VERSION ""

NS_ :

BS_:

BU_: CGEA12_TCU GWM PCM_HEV SOBDMC_HPCM_FD1 Vector__XXX

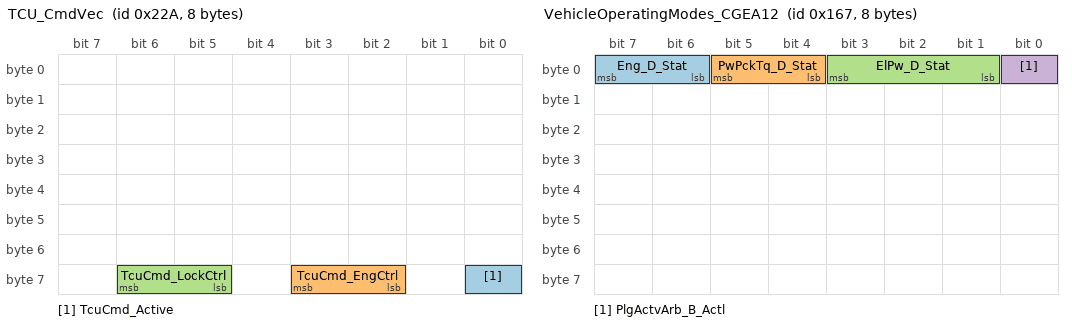
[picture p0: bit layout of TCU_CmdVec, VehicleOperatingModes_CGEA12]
BO_ 554 TCU_CmdVec: 8 CGEA12_TCU
 SG_ TcuCmd_Active   : 56|1@1+ (1,0) [0|1] "" Vector__XXX
 SG_ TcuCmd_EngCtrl  : 58|2@1+ (1,0) [0|3] "" Vector__XXX
 SG_ TcuCmd_LockCtrl : 61|2@1+ (1,0) [0|3] "" Vector__XXX

BO_ 359 VehicleOperatingModes_CGEA12: 8 PCM_HEV
 SG_ Eng_D_Stat        : 7|2@0+ (1,0) [0|3] "" CGEA12_TCU
 SG_ PwPckTq_D_Stat    : 5|2@0+ (1,0) [0|3] "" CGEA12_TCU
 SG_ ElPw_D_Stat       : 3|3@0+ (1,0) [0|7] "" CGEA12_TCU
 SG_ PlgActvArb_B_Actl : 0|1@0+ (1,0) [0|1] "" CGEA12_TCU

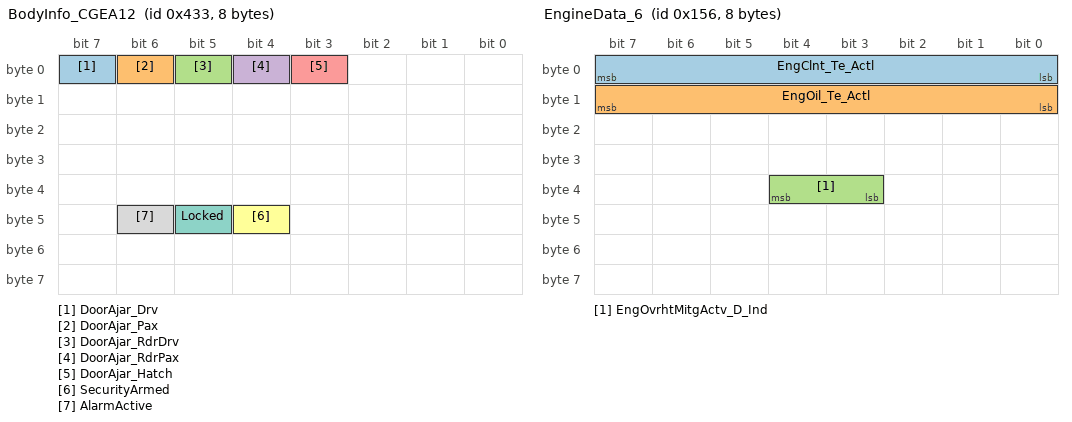
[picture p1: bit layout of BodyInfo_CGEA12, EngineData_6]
BO_ 1075 BodyInfo_CGEA12: 8 Vector__XXX
 SG_ DoorAjar_Drv    : 7|1@1+ (1,0) [0|1] "" CGEA12_TCU
 SG_ DoorAjar_Pax    : 6|1@1+ (1,0) [0|1] "" CGEA12_TCU
 SG_ DoorAjar_RdrDrv : 5|1@1+ (1,0) [0|1] "" CGEA12_TCU
 SG_ DoorAjar_RdrPax : 4|1@1+ (1,0) [0|1] "" CGEA12_TCU
 SG_ DoorAjar_Hatch  : 3|1@1+ (1,0) [0|1] "" CGEA12_TCU
 SG_ SecurityArmed   : 44|1@1+ (1,0) [0|1] "" CGEA12_TCU
 SG_ Locked          : 45|1@1+ (1,0) [0|1] "" CGEA12_TCU
 SG_ AlarmActive     : 46|1@1+ (1,0) [0|1] "" CGEA12_TCU

BO_ 1072 Cluster_Info1_FD1: 8 GWM
 SG_ OdometerMasterValue : 15|24@0+ (1,0) [0|16777214] "km" CGEA12_TCU

BO_ 342 EngineData_6: 8 PCM_HEV
 SG_ EngClnt_Te_Actl        : 7|8@0+  (1,-60) [-60|195] "degC"    CGEA12_TCU
 SG_ EngOil_Te_Actl         : 15|8@0+ (1,-60) [-60|193] "degC"    CGEA12_TCU
 SG_ EngOvrhtMitgActv_D_Ind : 36|2@0+ (1,0)   [0|3]     ""        CGEA12_TCU

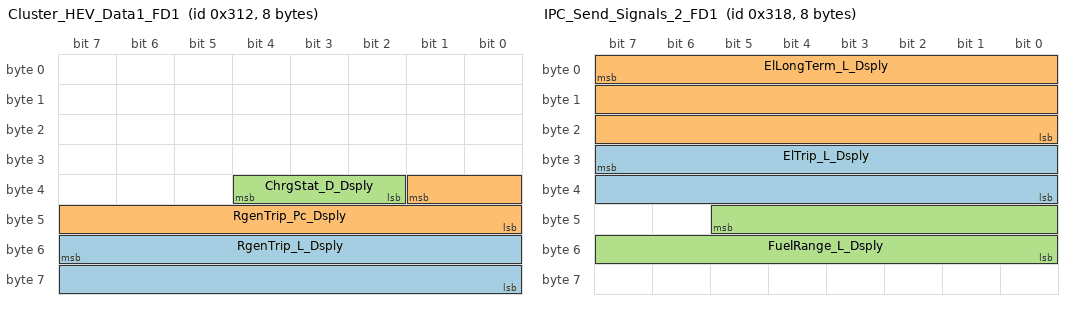
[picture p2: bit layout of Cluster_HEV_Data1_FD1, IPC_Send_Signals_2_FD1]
BO_ 786 Cluster_HEV_Data1_FD1: 8 SOBDMC_HPCM_FD1
 SG_ RgenTrip_L_Dsply  : 55|16@0+ (0.1,0) [0|6553.3] "km" CGEA12_TCU
 SG_ RgenTrip_Pc_Dsply : 33|10@0+ (0.1,0) [0|102.3] "percent" CGEA12_TCU
 SG_ ChrgStat_D_Dsply  : 36|3@0+ (1,0) [0|7] "" CGEA12_TCU

BO_ 792 IPC_Send_Signals_2_FD1: 8 GWM
 SG_ ElTrip_L_Dsply     : 31|16@0+ (0.1,0) [0|6553.3] "km" CGEA12_TCU
 SG_ ElLongTerm_L_Dsply : 7|24@0+ (0.1,0) [0|1677721.3] "km" CGEA12_TCU
 SG_ FuelRange_L_Dsply  : 45|14@0+ (0.1,0) [0|1638.3] "km" CGEA12_TCU

BO_ 791 Cluster_HEV_Data8_FD1: 8 GWM
 SG_ ConsAvgTrip_Fe_Dsply : 31|24@0+ (0.0001,0) [0|1677.7215] "l/100km" CGEA12_TCU

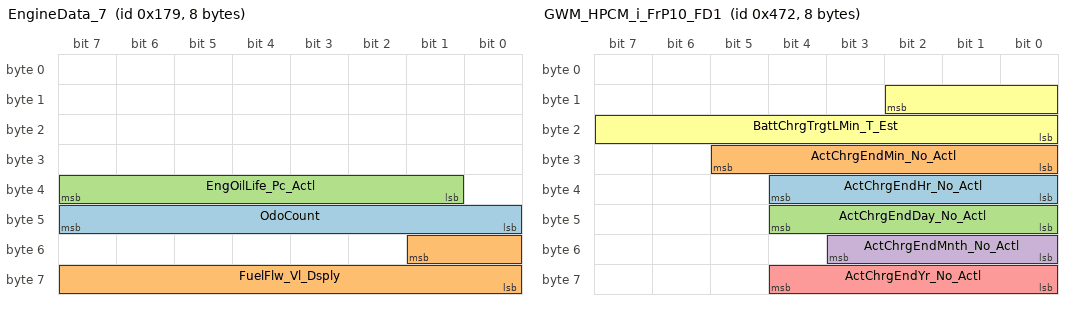
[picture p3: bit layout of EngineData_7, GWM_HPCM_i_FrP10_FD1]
BO_ 377 EngineData_7: 8 PCM_HEV
 SG_ OdoCount           : 47|8@0+ (0.2,0) [0|50.8]  "m"       CGEA12_TCU
 SG_ FuelFlw_Vl_Dsply   : 49|10@0+ (25,0) [0|25575] "uL"      CGEA12_TCU
 SG_ EngOilLife_Pc_Actl : 39|7@0+  (1,0)  [0|100]   "Percent" CGEA12_TCU

BO_ 729 HVAC_Setpt_CGEA12: 8 Vector__XXX
 SG_ HvacSetpt_Te : 16|8@1+ (0.5,-40) [-40|87.5] "degC" CGEA12_TCU

BO_ 1138 GWM_HPCM_i_FrP10_FD1: 8 SOBDMC_HPCM_FD1
 SG_ ActChrgEndHr_No_Actl   : 36|5@0+ (1,0) [0|29] "hour" CGEA12_TCU
 SG_ ActChrgEndMin_No_Actl  : 29|6@0+ (1,0) [0|61] "min" CGEA12_TCU
 SG_ ActChrgEndDay_No_Actl  : 44|5@0+ (1,1) [1|31] "day" CGEA12_TCU
 SG_ ActChrgEndMnth_No_Actl : 51|4@0+ (1,1) [1|15] "month" CGEA12_TCU
 SG_ ActChrgEndYr_No_Actl   : 60|5@0+ (1,2010) [2010|2040] "year" CGEA12_TCU
 SG_ BattChrgTrgtLMin_T_Est : 10|11@0+ (1,0) [0|2045] "min" CGEA12_TCU

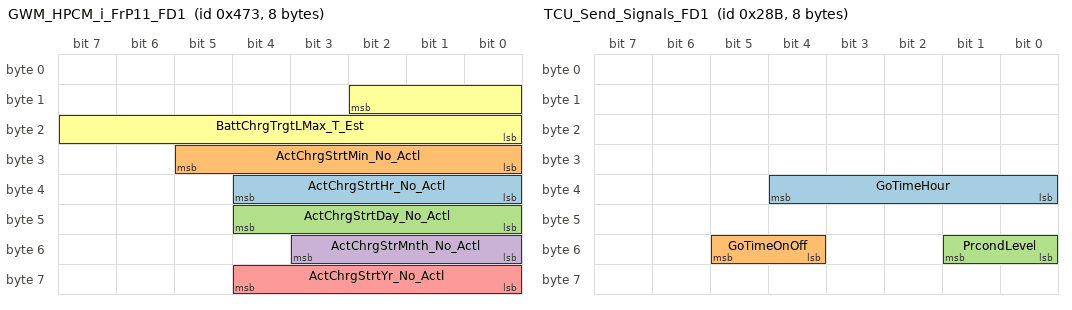
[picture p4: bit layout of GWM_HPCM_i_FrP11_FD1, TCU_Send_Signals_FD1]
BO_ 1139 GWM_HPCM_i_FrP11_FD1: 8 SOBDMC_HPCM_FD1
 SG_ ActChrgStrtHr_No_Actl   : 36|5@0+ (1,0) [0|29] "hour" CGEA12_TCU
 SG_ ActChrgStrtMin_No_Actl  : 29|6@0+ (1,0) [0|61] "min" CGEA12_TCU
 SG_ ActChrgStrtDay_No_Actl  : 44|5@0+ (1,1) [1|31] "day" CGEA12_TCU
 SG_ ActChrgStrMnth_No_Actl  : 51|4@0+ (1,1) [1|15] "month" CGEA12_TCU
 SG_ ActChrgStrtYr_No_Actl   : 60|5@0+ (1,2010) [2010|2040] "year" CGEA12_TCU
 SG_ BattChrgTrgtLMax_T_Est  : 10|11@0+ (1,0) [0|2045] "min" CGEA12_TCU

BO_ 651 TCU_Send_Signals_FD1: 8 Vector__XXX
 SG_ GoTimeHour  : 32|5@1+ (1,0) [0|31] "hour" CGEA12_TCU
 SG_ GoTimeOnOff : 52|2@1+ (1,0) [0|3] "" CGEA12_TCU
 SG_ PrcondLevel : 48|2@1+ (1,0) [0|3] "" CGEA12_TCU

BO_ 650 TCU_GoTimeDayOfWeek: 8 Vector__XXX
 SG_ GoTimeDayOfWeek : 61|3@1+ (1,0) [0|7] "" CGEA12_TCU

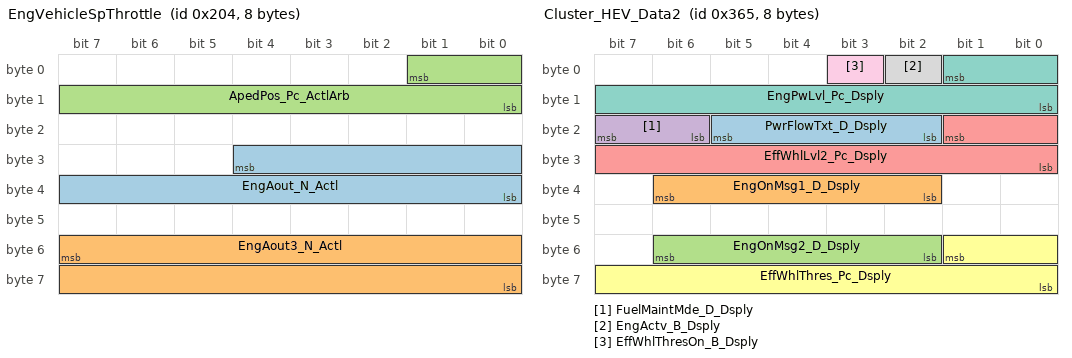
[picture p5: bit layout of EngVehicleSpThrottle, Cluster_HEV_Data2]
BO_ 516 EngVehicleSpThrottle: 8 PCM_HEV
 SG_ EngAout_N_Actl    : 28|13@0+ (2,0)    [0|16382]   "rpm" CGEA12_TCU
 SG_ EngAout3_N_Actl   : 55|16@0+ (0.25,0) [0|16383.5] "rpm" CGEA12_TCU
 SG_ ApedPos_Pc_ActlArb : 1|10@0+ (0.1,0)  [0|102.3]   "%"   CGEA12_TCU

BO_ 869 Cluster_HEV_Data2: 8 PCM_HEV
 SG_ PwrFlowTxt_D_Dsply   : 21|4@0+  (1,0)   [0|15]     ""        CGEA12_TCU
 SG_ EngOnMsg1_D_Dsply    : 38|5@0+  (1,0)   [0|31]     ""        CGEA12_TCU
 SG_ EngOnMsg2_D_Dsply    : 54|5@0+  (1,0)   [0|31]     ""        CGEA12_TCU
 SG_ FuelMaintMde_D_Dsply : 23|2@0+  (1,0)   [0|3]      ""        CGEA12_TCU
 SG_ EffWhlLvl2_Pc_Dsply  : 17|10@0+ (0.2,-102.2) [-102.2|102.4] "percent" CGEA12_TCU
 SG_ EffWhlThres_Pc_Dsply : 49|10@0+ (0.1,0) [0|102.3]  "percent" CGEA12_TCU
 SG_ EngPwLvl_Pc_Dsply    : 1|10@0+  (0.1,0) [0|102.3]  "percent" CGEA12_TCU
 SG_ EngActv_B_Dsply      : 2|1@0+   (1,0)   [0|1]      ""        CGEA12_TCU
 SG_ EffWhlThresOn_B_Dsply : 3|1@0+  (1,0)   [0|1]      ""        CGEA12_TCU

BO_ 872 Cluster_HEV_Data5: 8 PCM_HEV
 SG_ PlgActvArb_B_Dsply : 51|1@0+ (1,0) [0|1] "" CGEA12_TCU
 SG_ HybMdeStat_D_Dsply : 39|3@0+ (1,0) [0|7] "" CGEA12_TCU

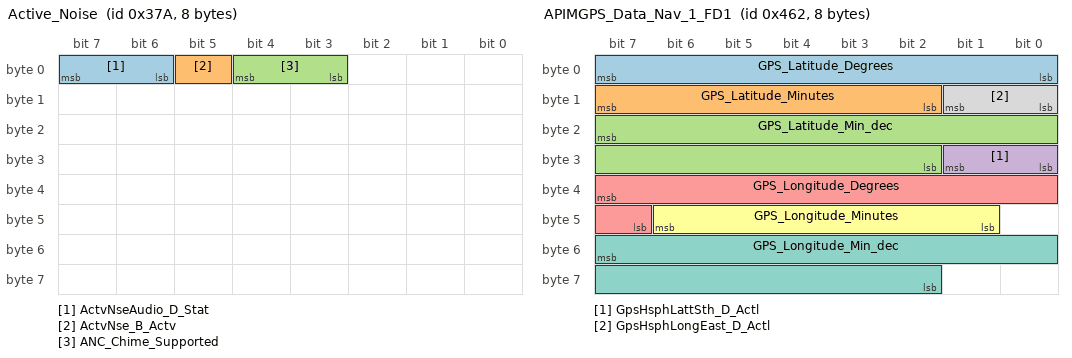
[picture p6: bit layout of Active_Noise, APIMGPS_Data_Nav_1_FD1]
BO_ 890 Active_Noise: 8 Vector__XXX
 SG_ ActvNseAudio_D_Stat  : 7|2@0+ (1,0) [0|3] "" CGEA12_TCU
 SG_ ActvNse_B_Actv       : 5|1@0+ (1,0) [0|1] "" CGEA12_TCU
 SG_ ANC_Chime_Supported  : 4|2@0+ (1,0) [0|3] "" CGEA12_TCU

BO_ 891 Active_Noise_Data: 8 Vector__XXX
 SG_ CabnSndAmb_Db_Actl : 7|8@0+ (1,30) [30|285] "decibel" CGEA12_TCU

CM_ BO_ 554 "TCU command vector transmitted by the CGEA1.2 custom TCU replacement on ID 0x22A. Byte7 carries three non-overlapping bit fields; bytes 0-6 are all-zero or uncharacterized. Wake burst: Active=0, all others=0 (0x00), sent at ~270us intervals until CAN traffic appears. Keepalive: Active=1, others=0 (0x01) at 1Hz. Remote start sequence: LockCtrl=Lock, wait ~1s, EngCtrl=RS_Stage2. Return to Keepalive after each command.";
CM_ SG_ 554 TcuCmd_Active "Byte7 bit0 — command active flag. 0=Wake burst (no command context), 1=Active (keepalive or command in progress). Always 1 for all normal operating commands.";
CM_ SG_ 554 TcuCmd_EngCtrl "Byte7 bits[3:2] — engine/remote-start control field. 0=None (keepalive/lock only), 1=RemoteStart_Stage2 (must follow Lock by ~1s), 2=RemoteStop. Return to 0 after command.";
CM_ SG_ 554 TcuCmd_LockCtrl "Byte7 bits[6:5] — lock control field. 0=None (keepalive/engine only), 1=Unlock, 2=Lock. Return to 0 after command. Combined command byte: Active|(EngCtrl<<2)|(LockCtrl<<5).";
CM_ BO_ 359 "Vehicle operating mode data on 0x167. Signal layout matches FD1 DBC (BO_ 359 VehicleOperatingModes) exactly — same Motorola bit positions for all four byte-0 signals. Transmitter confirmed as PCM_HEV on CGEA1.2.";
CM_ SG_ 359 Eng_D_Stat "Engine state from bits[7:6]. Typically 2 (EngAutoStopped) during EV driving as the ICE is managed by the HPCM. Transitions to 1 (EngOn) when the ICE is actively running (e.g., during ICE-on remote start or ICE engagement while driving).";
CM_ SG_ 359 PwPckTq_D_Stat "Hybrid powertrain torque availability from bits[5:4]. On this PHEV, TqAvailable(3) means ICE is running and providing torque; TqNotAvailable(1) means EV-only driving; Off(0) means powertrain not ready. Observed byte values: 0x80=Off+NoPlug, 0x81=Off+Plugged, 0x91=On_TqNotAvail+Plugged (EV driving), 0xA0=StartInPrgrss+NoPlug (remote crank), 0xA1=StartInPrgrss+Plugged (key crank), 0xB0=On_TqAvail+NoPlug (ICE run, remote start). 0xB1 (TqAvail+Plugged) not expected — vehicle cannot be put in gear while plugged in.";
CM_ SG_ 359 ElPw_D_Stat "Electric power state from bits[3:1]. Constant 0 (Not_Supported) on HEV/PHEV variants per FD1 DBC note — signal not used on this platform.";
CM_ SG_ 359 PlgActvArb_B_Actl "PHEV plug active arbitration from bit[0]. 1=plug arbitration active (car plugged in to charger or recently so). 0=plug not active (unplugged). Distinguishes key-start/charging context from remote-start/unplugged context. On Powersplit PHEVs, HPCM transmits; on MHT PHEVs, PCM_HEV transmits and HPCM receives.";
CM_ BO_ 1075 "CGEA1.2 body info message at 0x433. Encodes door ajar bitmask (byte0) and security/lock state (byte5). This is the CGEA1.2 functional equivalent of BCM_Lamp_Stat_FD1 (0x3C3 on FD1) — different CAN ID, same role. FD1 DBC signal Perimeter_Alarm_Status (0x3C3) is absent on CGEA1.2.";
CM_ SG_ 1075 DoorAjar_Drv "Driver front door ajar. 1=open, 0=closed. Bit7 of byte0 (mask 0x80). All five door signals share byte0.";
CM_ SG_ 1075 DoorAjar_Pax "Passenger front door ajar. 1=open, 0=closed. Bit6 of byte0 (mask 0x40).";
CM_ SG_ 1075 DoorAjar_RdrDrv "Driver rear door ajar. 1=open, 0=closed. Bit5 of byte0 (mask 0x20).";
CM_ SG_ 1075 DoorAjar_RdrPax "Passenger rear door ajar. 1=open, 0=closed. Bit4 of byte0 (mask 0x10).";
CM_ SG_ 1075 DoorAjar_Hatch "Rear hatch/liftgate ajar. 1=open, 0=closed. Bit3 of byte0 (mask 0x08).";
CM_ SG_ 1075 SecurityArmed "Byte5 bit4 (mask 0x10). 1=Armed/Locked, 0=Disarmed/Unlocked. Natural-polarity complement to Locked (bit5) — both should always read opposite states in normal operation. Transitional 0x80 is the only case where both are 0 simultaneously.";
CM_ SG_ 1075 Locked "Byte5 bit5 (mask 0x20). 0=Armed/Locked, 1=Disarmed/Unlocked. Inverted polarity — set bit means NOT armed. Complement to SecurityArmed (bit4). Observed byte5 values: 0x90=Armed, 0xA0=Disarmed, 0xD0=Alarm.";
CM_ SG_ 1075 AlarmActive "Byte5 bit6 (mask 0x40). 0=Normal, 1=Alarm active (horn sounding). Returns to 0 (~16s after horn starts) when car re-arms. Door-handle alarm: HS-CAN silent for ~5.6s between BCM wake and AlarmActive transition — IPC graduated beep (slow/medium/fast) occurs entirely off HS-CAN. Ignition-button alarm fires horn immediately with no IPC beep sequence.";
CM_ BO_ 1072 "Cluster info message. OdometerMasterValue confirmed on CGEA1.2 at same ID (0x430) and bit position as FD1 DBC. Value in km, unsigned 24-bit Motorola. Updates approximately every 100s of driving (1 km resolution).";
CM_ BO_ 342 "Engine coolant and oil temperatures confirmed on CGEA1.2 at same ID (0x156) and bit positions as FD1 DBC. Offset -60 degC confirmed by cold-soak: both signals read -2degC (~28F) at ambient ~30F. ICE typically starts ~456s into a cold drive on this PHEV platform. EngOvrhtMitgActv_D_Ind also confirmed present at same bit position.";
CM_ SG_ 342 EngOvrhtMitgActv_D_Ind "Engine overheat mitigation mode. 0=Normal_Mode (no action), 1=Mode1 (first-level mitigation active), 2=Mode2 (second-level mitigation active), 3=Undefined.";
CM_ BO_ 786 "Regen trip data and charge status. Signal positions match FD1 DBC exactly on CGEA1.2. RgenTrip_L_Dsply and RgenTrip_Pc_Dsply are fully confirmed. ChrgStat_D_Dsply is confirmed present with correct VAL_ labels (observed Complete=6 at drive start after full charge).";
CM_ BO_ 792 "EV trip and range signals. Positions match FD1 DBC on CGEA1.2. ElTrip_L_Dsply (current trip EV distance) and ElLongTerm_L_Dsply (lifetime EV odometer) are fully confirmed. FuelRange_L_Dsply is confirmed present but not independently verified against dash.";
CM_ BO_ 791 "Gas-only fuel consumption. ConsAvgTrip_Fe_Dsply is confirmed. Note: this is RAW GAS MPG only, not the MPGe shown on the dash. Dash MPGe combines gas + electric equivalent using EPA 33.705 kWh/gal factor. Example: 10.46 L/100km = 22.5 MPG gas-only, while dash displayed 46.7 MPGe for the same trip.";
CM_ BO_ 377 "Engine data including odometer tick counter, fuel flow, and oil life. OdoCount is confirmed — wrapping 8-bit counter, accumulate across rollovers (0->255->0) to get total distance. Factor 0.2m per count. Confirmed 3.91 mi total across a multi-log session. EngOilLife_Pc_Actl confirmed present at same bit position as FD1 DBC.";
CM_ SG_ 377 EngOilLife_Pc_Actl "Engine oil life remaining as a percentage. 7-bit Motorola field. Range 0-100%. Decreases over time and resets to 100 after an oil change.";
CM_ BO_ 729 "HVAC temperature setpoint at 0x2D9. Not present in any available DBC — located empirically. Byte2 encodes setpoint as: degC = (raw * 0.5) - 40. Confirmed: raw=119 -> 19.5degC (67.1F) matching user HVAC target. Full 8-byte frame is constant when setpoint is unchanged. Transmitter module not positively identified.";
CM_ BO_ 1138 "Actual charge session end time. Signal positions match FD1 DBC (GWM_HPCM_i_FrP10_FD1) exactly on CGEA1.2 at same ID. End time = estimated completion time based on current battery level and charge rate. Updates within ~1s of schedule changes via Sync. During Charge Now: shows estimated end time from current moment.";
CM_ BO_ 1139 "Actual charge session start time. Signal positions match FD1 DBC (GWM_HPCM_i_FrP11_FD1) exactly on CGEA1.2 at same ID. During Value Charge: shows next scheduled charge start datetime. During Charge Now: shows current datetime (immediate start). Updates at Sync save event.";
CM_ BO_ 651 "Go-time schedule signals carried in undocumented bit fields of 0x28B (TCU_Send_Signals_FD1). The three confirmed signals (GoTimeHour, GoTimeOnOff, PrcondLevel) are at byte4[4:0], byte6[5:4], and byte6[1:0] respectively — positions NOT documented in any available DBC. Go-time minutes field location not yet identified (all test saves used :00 minutes).";
CM_ SG_ 651 GoTimeHour "Go-time departure hour. 0-23=valid hour, 30=NoDataExists, 31=Faulty. Confirmed: value transitions to 4 after saving 4AM go-time, to 8 after saving 8AM. Minutes field not yet located.";
CM_ SG_ 651 GoTimeOnOff "Go-time enabled state. 1=Off, 2=On. Confirmed: transitions from Off(1) to On(2) when go-time is enabled in Sync.";
CM_ SG_ 651 PrcondLevel "Preconditioning level. 0=Off, 1=Low(65F), 2=Medium(72F), 3=High(80F). Low confirmed empirically. Medium and High values are from DBC VAL_ table — not independently tested.";
CM_ BO_ 650 "Go-time day-of-week field at 0x28A byte7[7:5]. Not in any DBC — located empirically. Confirmed: value=5 after saving Friday go-time profile.";
CM_ SG_ 650 GoTimeDayOfWeek "Day of week for the currently active go-time profile. 0=NotUsed, 1=Mon through 7=Sun. 3-bit field at byte7 bits[7:5] (Intel DBC position 61|3).";
CM_ BO_ 516 "Engine speed and accelerator pedal data at 0x204. Signal positions match FD1 DBC exactly on CGEA1.2. EngAout_N_Actl and EngAout3_N_Actl both represent engine RPM at different resolutions; EngAout3_N_Actl is HEV/PHEV only per FD1 DBC note. ApedPos_Pc_ActlArb is the arbitrated accelerator pedal position in percent.";
CM_ SG_ 516 EngAout_N_Actl "Engine output shaft speed in RPM. Factor 2 (raw*2=rpm). 13-bit Motorola field. Confirmed present on CGEA1.2 at same bit position as FD1 DBC.";
CM_ SG_ 516 EngAout3_N_Actl "Engine output shaft speed (high-resolution, HEV/PHEV only). Factor 0.25 (raw*0.25=rpm). 16-bit Motorola field. 65535=Invalid. Confirmed present on CGEA1.2 at same bit position as FD1 DBC.";
CM_ SG_ 516 ApedPos_Pc_ActlArb "Arbitrated accelerator pedal position as a percentage of full travel. Factor 0.1 (raw*0.1=%). Range 0-102.3%. Confirmed present on CGEA1.2 at same bit position as FD1 DBC.";
CM_ BO_ 869 "Hybrid powertrain display signals at 0x365. All signals match FD1 DBC (Cluster_HEV_Data2) positions exactly on CGEA1.2. Encodes the power flow screen text, ICE-on reason, fuel maintenance mode, efficiency gauge data, engine power level, and ICE activity flag.";
CM_ SG_ 869 PwrFlowTxt_D_Dsply "Active text displayed on the Sync hybrid power flow screen. 4-bit Motorola field. 0=No_Text when idle.";
CM_ SG_ 869 EngOnMsg1_D_Dsply "Primary reason the ICE is currently running, as displayed on the Sync power flow screen. 5-bit Motorola field. 0=No_Display when ICE is off.";
CM_ SG_ 869 EngOnMsg2_D_Dsply "Secondary/alternate ICE-on reason display field. Same VAL_ encoding as EngOnMsg1_D_Dsply. 5-bit Motorola field.";
CM_ SG_ 869 FuelMaintMde_D_Dsply "Fuel maintenance mode status. Activates when the PHEV has run primarily on EV for an extended period and the ICE needs to run to keep the fuel fresh. 0=OK, 1=Close_to_Fuel_Maint, 2=In_Fuel_Maint_Mode, 3=Feature_Not_Present.";
CM_ SG_ 869 EffWhlLvl2_Pc_Dsply "Efficiency wheel level 2 display value in percent. Factor 0.2, offset -102.2. Range -102.2 to 102.4%.";
CM_ SG_ 869 EffWhlThres_Pc_Dsply "Efficiency wheel threshold display value in percent. Factor 0.1. Range 0-102.3%.";
CM_ SG_ 869 EngPwLvl_Pc_Dsply "Engine power level as displayed on the Sync power flow screen, as a percentage of maximum. Factor 0.1. Range 0-102.3%.";
CM_ SG_ 869 EngActv_B_Dsply "ICE engine active flag for display purposes. 1=On (ICE running), 0=Off.";
CM_ SG_ 869 EffWhlThresOn_B_Dsply "Efficiency wheel threshold active flag. 1=On (threshold indicator displayed), 0=Off.";
CM_ BO_ 872 "Hybrid mode status and plug display signals at 0x368. Signal positions match FD1 DBC (Cluster_HEV_Data5) exactly on CGEA1.2. HybMdeStat_D_Dsply encodes the active hybrid operating mode. Note: FD1 DBC indicates HybMdeStat_D_Dsply is not transmitted by HPCM on FD1 — may differ on CGEA1.2.";
CM_ SG_ 872 PlgActvArb_B_Dsply "Plug active arbitration display flag. 1=On (plug active/charging), 0=Off. Display counterpart to PlgActvArb_B_Actl in BO_ 359.";
CM_ SG_ 872 HybMdeStat_D_Dsply "Hybrid operating mode status for display. 0=Null_State, 1=Auto_Charge_Deplete_Mode (normal EV priority), 2=Auto_Charge_Sustain_Mode, 3=Forced_Charge_Sustain_Mode, 4=Forced_EV_Mode, 5=EV_Override, 6=EV_Charge.";
CM_ BO_ 890 "Active noise cancellation status at 0x37A, sourced from the CGEA1.2 PT CAN DBC (Active_Noise). Encodes ANC system state and chime support. ActvNse_B_Actv confirmed to toggle with ICE running, consistent with ANC engaging when engine noise is present. No VAL_ tables in source DBC for the 2-bit fields.";
CM_ SG_ 890 ActvNse_B_Actv "Active noise cancellation active flag. 1=Active (ANC engaged, typically when ICE is running), 0=Inactive. Confirmed to correlate with ICE state on this PHEV.";
CM_ SG_ 890 ActvNseAudio_D_Stat "Active noise audio system status. 2-bit field. Encoding unconfirmed — no VAL_ table in source DBC.";
CM_ SG_ 890 ANC_Chime_Supported "Active noise cancellation chime support flag. 2-bit field. Likely a feature presence/capability indicator. Encoding unconfirmed — no VAL_ table in source DBC.";
CM_ BO_ 891 "Cabin ambient sound level at 0x37B, sourced from the CGEA1.2 PT CAN DBC (Active_Noise_Data). Single signal encoding the measured in-cabin noise level in decibels. Likely used by the active noise cancellation or audio compensation system.";
CM_ SG_ 891 CabnSndAmb_Db_Actl "Cabin ambient sound level in decibels. 8-bit Motorola field. Offset 30 (raw+30=dB value). Range 30–285 dB (practical values will be in the normal cabin noise range ~40–90 dB).";

 0 "Wake_Burst"
 1 "Active" ;

 0 "None"
 1 "RemoteStart_Stage2"
 2 "RemoteStop"
 3 "Reserved" ;

 0 "None"
 1 "Unlock"
 2 "Lock"
 3 "Reserved" ;

 0 "EngOff"
 1 "EngOn"
 2 "EngAutoStopped"
 3 "NotUsed" ;

 0 "PwPckOff_TqNotAvailable"
 1 "PwPckOn_TqNotAvailable"
 2 "StartInPrgrss_TqNotAvail"
 3 "PwPckOn_TqAvailable" ;

 0 "Not_Supported"
 1 "Supported"
 2 "Not_Supported_Imminent"
 3 "LV_Event_In_Progress"
 4 "Fault_Limited" ;

 0 "Off"
 1 "On" ;

 0 "Closed"
 1 "Open" ;

 0 "Closed"
 1 "Open" ;

 0 "Closed"
 1 "Open" ;

 0 "Closed"
 1 "Open" ;

 0 "Closed"
 1 "Open" ;

 0 "Disarmed"
 1 "Armed" ;
 0 "Locked"
 1 "Unlocked" ;

 0 "Normal"
 1 "Alarming" ;

 7 "NotUsed"
 6 "Complete"
 5 "Scheduled"
 4 "In_Progress"
 3 "Fault_Outside_Car"
 2 "Fault_Inside_Car"
 1 "Fault_Unknown_Location"
 0 "Not_Ready" ;

 0 "Null"
 1 "Off"
 2 "On"
 3 "NotUsed" ;

 0 "Off"
 1 "Low_65F"
 2 "Medium_72F"
 3 "High_80F" ;

 0 "NotUsed"
 1 "Monday"
 2 "Tuesday"
 3 "Wednesday"
 4 "Thursday"
 5 "Friday"
 6 "Saturday"
 7 "Sunday" ;

 16777215 "Invalid" ;

 0 "Normal_Mode"
 1 "Mode1"
 2 "Mode2"
 3 "Undefined" ;

 65535 "Invalid" ;

 0  "No_Text"
 1  "Disp_Hyb_Drive_Txt"
 2  "Disp_Charg_HV_Batt_Txt"
 3  "Disp_Idle_Txt"
 4  "Disp_Idle_with_Chrg_Txt"
 5  "Disp_Elec_Drv_Txt"
 6  "Disp_Eng_Drv_Txt"
 7  "Disp_Remote_Start_Txt"
 8  "Disp_Charge_Cmplt_Txt"
 9  "Disp_Fast_Charge_Cmplt_Txt"
 10 "Disp_Fast_Charge_Txt"
 11 "Disply_Rgen_Chrg_Txt"
 12 "NotUsed4"
 13 "NotUsed5"
 14 "NotUsed6"
 15 "NotUsed7" ;

 0  "No_Display"
 1  "Acceleration"
 2  "High_Speed"
 3  "Heater_Setting"
 4  "Neutral_Gear"
 5  "Engine_Cold"
 6  "Batt_Charging"
 7  "Low_Gear"
 8  "Normal_Operation"
 9  "Oil_Maintenance"
 10 "Fuel_Maintenance"
 11 "Hill_Decent_Control"
 12 "Battery_Temperature"
 13 "Drive_Mode_Selection"
 14 "_0xE_to_1F_NotUsed" ;

 0  "No_Display"
 1  "Acceleration"
 2  "High_Speed"
 3  "Heater_Setting"
 4  "Neutral_Gear"
 5  "Engine_Cold"
 6  "Batt_Charging"
 7  "Low_Gear"
 8  "Normal_Operation"
 9  "Oil_Maintenance"
 10 "Fuel_Maintenance"
 11 "Hill_Decent_Control"
 12 "Battery_Temperature"
 13 "Drive_Mode_Selection"
 14 "_0xE_to_1F_NotUsed" ;

 0 "OK"
 1 "Close_to_Fuel_Maint"
 2 "In_Fuel_Maint_Mode"
 3 "Feature_Not_Present" ;

 0 "Off"
 1 "On" ;

 0 "Off"
 1 "On" ;

 0 "Off"
 1 "On" ;

 0 "Inactive"
 1 "Active" ;

 0 "Null_State"
 1 "Auto_Charge_Deplete_Mode"
 2 "Auto_Charge_Sustain_Mode"
 3 "Forced_Charge_Sustain_Mode"
 4 "Forced_EV_Mode"
 5 "EV_Override"
 6 "EV_Charge"
 7 "NotUsed2" ;

BO_ 1122 APIMGPS_Data_Nav_1_FD1: 8 GWM
 SG_ GPS_Latitude_Degrees  : 7|8@0+  (1,-89)     [-89|164]    "Degrees" CGEA12_TCU
 SG_ GPS_Latitude_Minutes  : 15|6@0+ (1,0)        [0|61]       "Minutes" CGEA12_TCU
 SG_ GPS_Latitude_Min_dec  : 23|14@0+ (0.0001,0)  [0|1.6381]  "Minutes" CGEA12_TCU
 SG_ GpsHsphLattSth_D_Actl : 25|2@0+ (1,0)        [0|3]        "SED"    CGEA12_TCU
 SG_ GPS_Longitude_Degrees : 39|9@0+ (1,-179)     [-179|330]   "Degrees" CGEA12_TCU
 SG_ GPS_Longitude_Minutes : 46|6@0+ (1,0)        [0|61]       "Minutes" CGEA12_TCU
 SG_ GPS_Longitude_Min_dec : 55|14@0+ (0.0001,0)  [0|1.6381]  "Minutes" CGEA12_TCU
 SG_ GpsHsphLongEast_D_Actl : 9|2@0+ (1,0)        [0|3]        "SED"    CGEA12_TCU

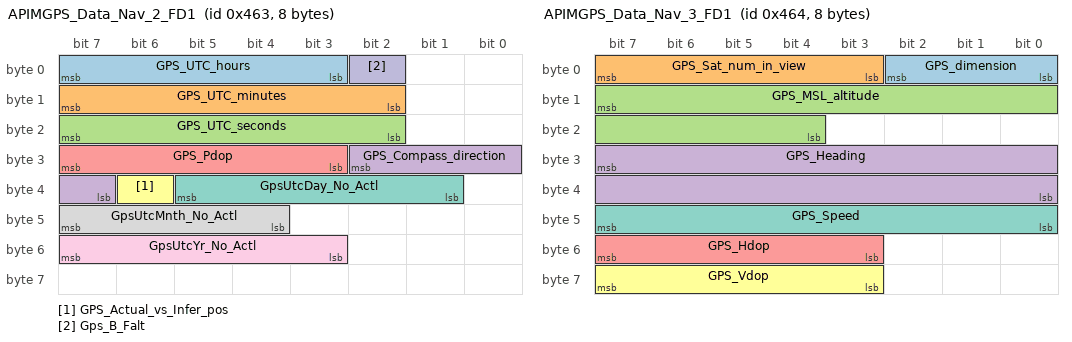
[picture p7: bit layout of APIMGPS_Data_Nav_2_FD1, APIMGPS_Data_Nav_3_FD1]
BO_ 1123 APIMGPS_Data_Nav_2_FD1: 8 GWM
 SG_ GPS_UTC_hours          : 7|5@0+  (1,0)       [0|23]       "Hours"   CGEA12_TCU
 SG_ GPS_UTC_minutes        : 15|6@0+ (1,0)       [0|59]       "Minutes" CGEA12_TCU
 SG_ GPS_UTC_seconds        : 23|6@0+ (1,0)       [0|59]       "seconds" CGEA12_TCU
 SG_ GPS_Compass_direction  : 26|4@0+ (1,0)       [0|15]       "SED"     CGEA12_TCU
 SG_ GPS_Pdop               : 31|5@0+ (0.2,0)     [0|5.8]      "unitless" CGEA12_TCU
 SG_ GPS_Actual_vs_Infer_pos : 38|1@0+ (1,0)      [0|1]        "SED"     CGEA12_TCU
 SG_ GpsUtcDay_No_Actl      : 37|5@0+ (1,1)       [1|32]       "Day"     CGEA12_TCU
 SG_ GpsUtcMnth_No_Actl     : 47|4@0+ (1,1)       [1|15]       "Month"   CGEA12_TCU
 SG_ GpsUtcYr_No_Actl       : 55|5@0+ (1,2010)    [2010|2040]  "Year"    CGEA12_TCU
 SG_ Gps_B_Falt             : 2|1@0+  (1,0)       [0|1]        "SED"     CGEA12_TCU

BO_ 1124 APIMGPS_Data_Nav_3_FD1: 8 GWM
 SG_ GPS_dimension          : 2|3@0+  (1,0)       [0|7]        "SED"     CGEA12_TCU
 SG_ GPS_Sat_num_in_view    : 7|5@0+  (1,0)       [0|29]       "unitless" CGEA12_TCU
 SG_ GPS_MSL_altitude       : 15|12@0+ (10,-20460) [-20460|20470] "feet" CGEA12_TCU
 SG_ GPS_Heading            : 31|16@0+ (0.01,0)   [0|655.33]   "Degrees" CGEA12_TCU
 SG_ GPS_Hdop               : 55|5@0+ (0.2,0)     [0|5.8]      "unitless" CGEA12_TCU
 SG_ GPS_Vdop               : 63|5@0+ (0.2,0)     [0|5.8]      "unitless" CGEA12_TCU
 SG_ GPS_Speed              : 47|8@0+ (1,0)        [0|253]      "MPH"     CGEA12_TCU

CM_ BO_ 1122 "GPS position data from the APIM (Sync) GPS receiver, broadcast on HS-CAN. Confirmed present on CGEA1.2 (same IDs and signal positions as FD1 DBC). Latitude and longitude are encoded as degrees + minutes + fractional minutes with separate hemisphere flags. To reconstruct decimal degrees: lat = (GPS_Latitude_Degrees + GPS_Latitude_Minutes/60 + GPS_Latitude_Min_dec/60) * (GpsHsphLattSth_D_Actl==1 ? -1 : 1); lon = (GPS_Longitude_Degrees + GPS_Longitude_Minutes/60 + GPS_Longitude_Min_dec/60) * (GpsHsphLongEast_D_Actl==2 ? -1 : 1).";
CM_ SG_ 1122 GPS_Latitude_Degrees "Integer degrees of latitude. Offset -89 applied by DBC (raw+offset=value). Valid range -89 to 90. 254=Unknown, 255=Invalid.";
CM_ SG_ 1122 GPS_Longitude_Degrees "Integer degrees of longitude. Offset -179 applied by DBC (raw+offset=value). Valid range -179 to 180. 510=Unknown, 511=Fault.";
CM_ SG_ 1122 GpsHsphLattSth_D_Actl "Latitude hemisphere: 2=Northern, 1=Southern, 0=Invalid, 3=Fault.";
CM_ SG_ 1122 GpsHsphLongEast_D_Actl "Longitude hemisphere: 1=Eastern, 2=Western, 0=Invalid, 3=Fault.";
CM_ BO_ 1123 "GPS UTC timestamp and fix quality data. UTC time confirmed valid to approx +/-0.5s against NTP reference during testing. GPS data typically appears 17-752ms after a CAN bus wake cycle. Gps_B_Falt=1 indicates GPS module fault.";
CM_ SG_ 1123 GPS_UTC_hours "UTC hour (0-23). 30=Unknown, 31=Invalid.";
CM_ SG_ 1123 GPS_Pdop "Position dilution of precision. Factor 0.2 (raw*0.2=value). Lower=better fix quality. 30=Unknown, 31=Invalid.";
CM_ BO_ 1124 "GPS fix quality, speed, heading, and satellite data. GPS_dimension indicates fix type: 0=No_Fix, 1=2D, 2=3D. GPS_Speed in MPH (254=Unknown, 255=Invalid). GPS_Heading in degrees 0-360 (0.01 deg resolution). Altitude in feet above MSL with offset -20460.";
CM_ SG_ 1124 GPS_dimension "GPS fix dimension: 0=No_Fix (no valid position), 1=2D fix, 2=3D fix.";
CM_ SG_ 1124 GPS_Heading "True heading in degrees. Factor 0.01 (raw*0.01=value). 65534=Unknown, 65535=Fault.";
CM_ SG_ 1124 GPS_MSL_altitude "Altitude above mean sea level in feet. Factor 10, offset -20460 (raw*10-20460=value). 4094=Unknown, 4095=Fault.";

 3 "Fault"
 2 "Northern"
 1 "Southern"
 0 "Invalid" ;

 3 "Fault"
 2 "Western"
 1 "Eastern"
 0 "Invalid" ;

 255 "Invalid"
 254 "Unknown" ;

 63 "Fault"
 62 "Unknown" ;

 16383 "Invalid"
 16382 "Unknown" ;

 511 "Fault"
 510 "Unknown" ;

 63 "Fault"
 62 "Unknown" ;

 16383 "Invalid"
 16382 "Unknown" ;

 31 "Invalid"
 30 "Unknown" ;

 63 "Fault"
 62 "Unknown" ;

 63 "Fault"
 62 "Unknown" ;

 7 "NorthWest"
 6 "West"
 5 "SouthWest"
 4 "South"
 3 "SouthEast"
 2 "East"
 1 "NorthEast"
 0 "North" ;

 31 "Invalid"
 30 "Unknown" ;

 1 "Inferred_Position"
 0 "Actual_Position" ;

 1 "Yes"
 0 "No" ;

 31 "Fault" ;

 15 "Fault" ;

 2 "_3D"
 1 "_2D"
 0 "No_Fix" ;

 255 "Invalid"
 254 "Unknown" ;

 31 "Invalid"
 30 "Unknown" ;

 4095 "Fault"
 4094 "Unknown" ;

 65535 "Fault"
 65534 "Unknown" ;

 31 "Invalid"
 30 "Unknown" ;

 31 "Invalid"
 30 "Unknown" ;
